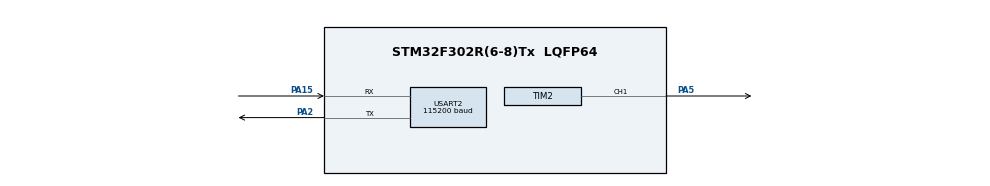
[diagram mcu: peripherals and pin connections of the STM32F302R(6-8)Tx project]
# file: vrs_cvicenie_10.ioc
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Dma.Request0=USART2_RX
Dma.Request1=USART2_TX
Dma.USART2_RX.0.Direction=DMA_PERIPH_TO_MEMORY
Dma.USART2_RX.0.Instance=DMA1_Channel6
Dma.USART2_RX.0.MemDataAlignment=DMA_MDATAALIGN_BYTE
Dma.USART2_RX.0.MemInc=DMA_MINC_ENABLE
Dma.USART2_RX.0.Mode=DMA_NORMAL
Dma.USART2_RX.0.PeriphDataAlignment=DMA_PDATAALIGN_BYTE
Dma.USART2_RX.0.PeriphInc=DMA_PINC_DISABLE
Dma.USART2_RX.0.Priority=DMA_PRIORITY_MEDIUM
Dma.USART2_TX.1.Direction=DMA_MEMORY_TO_PERIPH
Dma.USART2_TX.1.Instance=DMA1_Channel7
Dma.USART2_TX.1.MemDataAlignment=DMA_MDATAALIGN_BYTE
Dma.USART2_TX.1.MemInc=DMA_MINC_ENABLE
Dma.USART2_TX.1.Mode=DMA_NORMAL
Dma.USART2_TX.1.PeriphDataAlignment=DMA_PDATAALIGN_BYTE
Dma.USART2_TX.1.PeriphInc=DMA_PINC_DISABLE
Dma.USART2_TX.1.Priority=DMA_PRIORITY_MEDIUM
Mcu.Family=STM32F3
Mcu.Name=STM32F302R(6-8)Tx
Mcu.Package=LQFP64
NVIC.DMA1_Channel6_IRQn=true\:0\:0\:false\:false\:true\:false\:true
NVIC.DMA1_Channel7_IRQn=true\:0\:0\:false\:false\:true\:false\:true
NVIC.PriorityGroup=NVIC_PRIORITYGROUP_4
NVIC.TIM2_IRQn=true\:0\:0\:false\:false\:true\:true\:true
NVIC.USART2_IRQn=true\:0\:0\:false\:false\:true\:true\:true
PA15.Mode=Asynchronous
PA15.Signal=USART2_RX
PA2.Mode=Asynchronous
PA2.Signal=USART2_TX
PA5.Signal=S_TIM2_CH1_ETR
ProjectManager.HeapSize=0x200
ProjectManager.StackSize=0x400
ProjectManager.TargetToolchain=STM32CubeIDE
RCC.AHBFreq_Value=8000000
RCC.APB1Freq_Value=8000000
RCC.APB2Freq_Value=8000000
RCC.CortexFreq_Value=8000000
RCC.HSE_VALUE=8000000
RCC.HSI_VALUE=8000000
RCC.LSE_VALUE=32768
RCC.SYSCLKFreq_VALUE=8000000
SH.S_TIM2_CH1_ETR.0=TIM2_CH1,PWM Generation1 CH1
TIM2.Channel-PWM\ Generation1\ CH1=TIM_CHANNEL_1
TIM2.CounterMode=TIM_COUNTERMODE_UP
TIM2.OC1Preload_PWM=DISABLE
TIM2.Period=9
TIM2.Prescaler=7999
USART2.BaudRate=115200
USART2.VirtualMode-Asynchronous=VM_ASYNC
VP_TIM2_VS_ClockSourceINT.Mode=Internal
board=custom

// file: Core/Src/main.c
/* USER CODE BEGIN Header */
/**
  ******************************************************************************
  * @file           : main.c
  * @brief          : Main program body
  ******************************************************************************
  * @attention
  *
  * <h2><center>&copy; Copyright (c) 2021 STMicroelectronics.
  * All rights reserved.</center></h2>
  *
  * This software component is licensed by ST under BSD 3-Clause license,
  * the "License"; You may not use this file except in compliance with the
  * License. You may obtain a copy of the License at:
  *                        opensource.org/licenses/BSD-3-Clause
  *
  ******************************************************************************
  */
/* USER CODE END Header */
#include "main.h"
#include "dma.h"
#include "tim.h"
#include "usart.h"
#include "gpio.h"

/* USER CODE BEGIN Includes */
#include "string.h"
#include "float.h"
#include "stdlib.h"
#include "stdio.h"
//#include "iostream.h"
/* USER CODE END Includes */

/* USER CODE BEGIN PD */
void proccesDmaData(const uint8_t* sign, uint16_t len);
void print();
/* USER CODE END PD */

/* USER CODE BEGIN PV */
uint8_t count = 0;
int male = 0, velke = 0;
int start = 0;
int velkost = 256;
letter_count_ letters;

uint8_t string[20];

uint8_t tx_data[] = "Data to send over UART DMA!\n\r";
uint8_t rx_data[10];

uint8_t buffer[4];
uint8_t memory[4];
uint8_t load[4];
char stav[7];
uint8_t velke_pismena[4];

uint16_t occupiedMem;

int dollar = 0;

char state_manual[6] = "manual";
char state_auto[4] = "auto";
char pwm_char[3] = "PWM";
extern int state = 0;						//Počiatočný stav 0, Auto = 1, Man = 2

int pwm = 0;

int cislo = 0;

extern int num = -1;
/* USER CODE END PV */

void SystemClock_Config(void);

int main(void)
{

  /* MCU Configuration--------------------------------------------------------*/

  /* Reset of all peripherals, Initializes the Flash interface and the Systick. */

  LL_APB2_GRP1_EnableClock(LL_APB2_GRP1_PERIPH_SYSCFG);
  LL_APB1_GRP1_EnableClock(LL_APB1_GRP1_PERIPH_PWR);

  NVIC_SetPriorityGrouping(NVIC_PRIORITYGROUP_4);

  /* System interrupt init*/
  /* SysTick_IRQn interrupt configuration */
  NVIC_SetPriority(SysTick_IRQn, NVIC_EncodePriority(NVIC_GetPriorityGrouping(),15, 0));

  /* Configure the system clock */
  SystemClock_Config();

  /* Initialize all configured peripherals */
  MX_GPIO_Init();
  MX_DMA_Init();
  MX_USART2_UART_Init();
  MX_TIM2_Init();
  /* USER CODE BEGIN 2 */
  USART2_RegisterCallback(proccesDmaData);
  LL_TIM_CC_EnableChannel(TIM2, LL_TIM_CHANNEL_CH1);
  LL_TIM_EnableIT_UPDATE(TIM2);
  LL_TIM_EnableCounter(TIM2);
  /* USER CODE END 2 */

  /* Infinite loop */
  while (1)
  {

    /* USER CODE BEGIN 3 */
	  print();
	  LL_mDelay(1000);
  }
  /* USER CODE END 3 */
}

void SystemClock_Config(void)
{
	LL_FLASH_SetLatency(LL_FLASH_LATENCY_0);

	if(LL_FLASH_GetLatency() != LL_FLASH_LATENCY_0)
	{
		Error_Handler();
	}
	LL_RCC_HSI_Enable();

	/* Wait till HSI is ready */
	while(LL_RCC_HSI_IsReady() != 1)
	{

	}
	LL_RCC_HSI_SetCalibTrimming(16);
	LL_RCC_SetAHBPrescaler(LL_RCC_SYSCLK_DIV_1);
	LL_RCC_SetAPB1Prescaler(LL_RCC_APB1_DIV_1);
	LL_RCC_SetAPB2Prescaler(LL_RCC_APB1_DIV_1);
	LL_RCC_SetSysClkSource(LL_RCC_SYS_CLKSOURCE_HSI);

	/* Wait till System clock is ready */
	while(LL_RCC_GetSysClkSource() != LL_RCC_SYS_CLKSOURCE_STATUS_HSI)
	{

	}
	LL_Init1msTick(8000000);
	LL_SYSTICK_SetClkSource(LL_SYSTICK_CLKSOURCE_HCLK);
	LL_SetSystemCoreClock(8000000);
}

/* USER CODE BEGIN 4 */
void print(){
	uint8_t s1[] = "Buffer capacity: ";
	uint8_t s2[] = "bytes, occupied memory: ";
	uint8_t s3[] = "bytes, load [in %]: ";
	uint8_t s4[] = "%\n\r";
	uint8_t s5[] = "Aktualny stav: ";
	uint8_t s6[] = "	Pocet velkych pismen: ";
	uint8_t s7[] = "\n\r";
	uint16_t buffer_size =  DMA_USART2_BUFFER_SIZE;
	float pom_occupiedMem = occupiedMem;
	float pom_buffer_size = buffer_size;
	float percento = (pom_occupiedMem/pom_buffer_size)*100.0;

	sprintf(buffer, "%d", buffer_size);
	strcat(s1, buffer);

	USART2_PutBuffer(s1, strlen(s1));
	LL_mDelay(50);

	sprintf(memory, "%d", occupiedMem);
	strcat(s2, memory);

	USART2_PutBuffer(s2, strlen(s2));
	LL_mDelay(50);

	gcvt(percento, 6, load);
	strcat(s3, load);

	USART2_PutBuffer(s3, strlen(s3));
	LL_mDelay(50);

	USART2_PutBuffer(s4, strlen(s4));
	LL_mDelay(50);

	if((state == 0) || (state == 1)){
		strcat(s5, " auto");
	}
	else if (state == 2){
		strcat(s5, " manual");
	}

	strcat(s5, stav);

	USART2_PutBuffer(s5, strlen(s5));
	LL_mDelay(50);

	USART2_PutBuffer(s7, strlen(s7));
	LL_mDelay(50);
	USART2_PutBuffer(s7, strlen(s7));
	LL_mDelay(50);
}

void proccesDmaData(const uint8_t* sign, uint16_t len)
{
	/* Process received data */

	uint8_t pom = 0;
	int count;
	int count_1 = 0;
		// type your algorithm here:

	while(pom < len){
	uint8_t akt = *(sign+pom);
		if(*(sign+pom) == '$'){
			++dollar;
			start = 1;
			male = 0;
			count = 0;
			velke = 0;

			if(dollar >= 2){
				start = 0;

				letters.capital_letter = letters.capital_letter + velke;
				letters.small_letter = letters.small_letter + male;

				dollar = 0;
			}
		}

		if(start == 1){

			if(*(sign+pom) == state_manual[count_1]){
				count_1++;
				if(count_1 == 6){		//manual
					state = 2;

					count_1 = 0;
				}
			}

			else if((*(sign+pom) != state_manual[count_1]) && (*(sign+pom) == state_auto[count_1])){
				count_1++;
				if(count_1 == 4){		//auto
					state = 1;
					count_1 = 0;
					num = -1;
				}
			}

			if(state == 2){
				if(*(sign+pom) == pwm_char[count_1]){
					count_1++;
					if(count_1 == 3){		//pwm
						pwm = 1;

						count_1 = 0;
					}
				}
				if(pwm == 1){
					++count_1;
					cislo = (int)(*(sign+(pom+1)));
					if(count_1 == 1){
						num = (cislo-48)*10;
					}
					else if(count_1 == 2){
						num = num+(cislo-48);
					}
					if(count_1 == 2){
						//num = atol(cislo);
						//num = (int)(cislo);
						if(num >= 0 && num < 100){
							//signal PWM
							pwm = 0;
							count_1 = 0;
							//state = 0;
						}

					}

				}
			}

			count++;
		}

		if(dollar >= 2){
			if(state == 1){
				// Pustanie LED auto

				state = 0;
			}
			else if(state == 2){
				//Pustanie LED manual

				state = 0;
			}
		}

		if(count == 35 && *(sign+pom) != '$'){
			start = 0;
			male = 0;
			count = 0;
			velke = 0;
		}
		pom++;
	}
}
/* USER CODE END 4 */

void Error_Handler(void)
{
  __disable_irq();
  while (1)
  {
  }
}

/************************ (C) COPYRIGHT STMicroelectronics *****END OF FILE****/
